# STM32L151 register map
File version: 1.5
CPU: CM3 r1p1, little endian, no MPU, no FPU, 4 interrupt priority bits
Registers are 32-bit, read-write, reset 0x0 unless marked. A register's access mark holds for its fields unless they carry their own. Offsets are from the block's base; [hi:lo] are bit positions; {n}, {i} and the like mark numbered series.

## USB — Universal serial bus full-speed device interface
Base 0x40005C00
Same registers: USB_SRAM 0x40006000
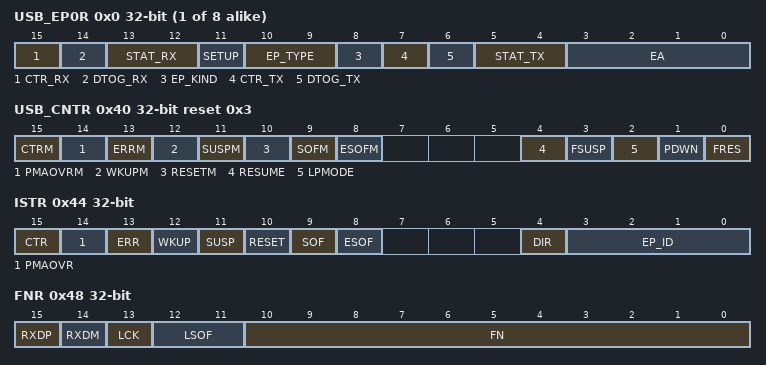
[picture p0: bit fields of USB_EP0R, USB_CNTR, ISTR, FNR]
{0x0+4i} USB_EP{i}R (i=0..7) — endpoint {i} register
  [15] CTR_RX — Correct transfer for reception
  [14] DTOG_RX — Data Toggle, for reception transfers
  [13:12] STAT_RX — Status bits, for reception transfers
  [11] SETUP — Setup transaction completed
  [10:9] EP_TYPE — Endpoint type
  [8] EP_KIND — Endpoint kind
  [7] CTR_TX — Correct Transfer for transmission
  [6] DTOG_TX — Data Toggle, for transmission transfers
  [5:4] STAT_TX — Status bits, for transmission transfers
  [3:0] EA — Endpoint address
0x40 USB_CNTR reset 0x3 — control register
  [15] CTRM — Correct transfer interrupt mask
  [14] PMAOVRM — Packet memory area over / underrun interrupt mask
  [13] ERRM — Error interrupt mask
  [12] WKUPM — Wakeup interrupt mask
  [11] SUSPM — Suspend mode interrupt mask
  [10] RESETM — USB reset interrupt mask
  [9] SOFM — Start of frame interrupt mask
  [8] ESOFM — Expected start of frame interrupt mask
  [4] RESUME — Resume request
  [3] FSUSP — Force suspend
  [2] LPMODE — Low-power mode
  [1] PDWN — Power down
  [0] FRES — Force USB Reset
0x44 ISTR — interrupt status register
  [15] CTR — Correct transfer
  [14] PMAOVR — Packet memory area over / underrun
  [13] ERR — Error
  [12] WKUP — Wakeup
  [11] SUSP — Suspend mode request
  [10] RESET — reset request
  [9] SOF — start of frame
  [8] ESOF — Expected start frame
  [4] DIR — Direction of transaction
  [3:0] EP_ID — Endpoint Identifier
0x48 FNR ro — frame number register
  [15] RXDP — Receive data + line status
  [14] RXDM — Receive data - line status
  [13] LCK — Locked
  [12:11] LSOF — Lost SOF
  [10:0] FN — Frame number
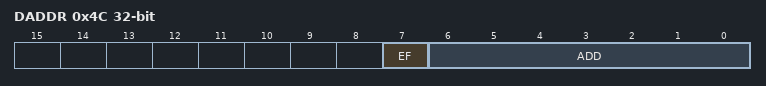
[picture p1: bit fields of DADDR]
0x4C DADDR — device address
  [7] EF — Enable function
  [6:0] ADD — Device address
0x50 BTABLE — Buffer table address
  [15:3] BTABLE — Buffer table

## WWDG — Window watchdog
Base 0x40002C00
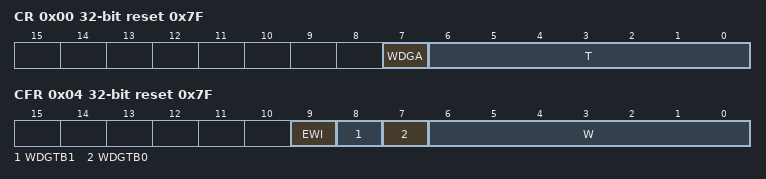
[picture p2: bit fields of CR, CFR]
0x00 CR access per field reset 0x7F — Control register
  [7] WDGA wo — Activation bit
  [6:0] T rw — 7-bit counter (MSB to LSB)
0x04 CFR access per field reset 0x7F — Configuration register
  [9] EWI wo — Early wakeup interrupt
  [8] WDGTB1 rw — Timer base
  [7] WDGTB0 rw
  [6:0] W rw — 7-bit window value
0x08 SR
  [0] EWIF

## NVIC — Nested Vectored Interrupt Controller
Base 0xE000E100
0x00 ISER0 — Interrupt Set-Enable Register
  [31:0] SETENA
0x04 ISER1 — Interrupt Set-Enable Register
  [31:0] SETENA
0x80 ICER0 — Interrupt Clear-Enable Register
  [31:0] CLRENA
0x84 ICER1 — Interrupt Clear-Enable Register
  [31:0] CLRENA
0x100 ISPR0 — Interrupt Set-Pending Register
  [31:0] SETPEND
0x104 ISPR1 — Interrupt Set-Pending Register
  [31:0] SETPEND
0x180 ICPR0 — Interrupt Clear-Pending Register
  [31:0] CLRPEND
0x184 ICPR1 — Interrupt Clear-Pending Register
  [31:0] CLRPEND
0x200 IABR0 ro — Interrupt Active Bit Register
  [31:0] ACTIVE
0x204 IABR1 ro — Interrupt Active Bit Register
  [31:0] ACTIVE
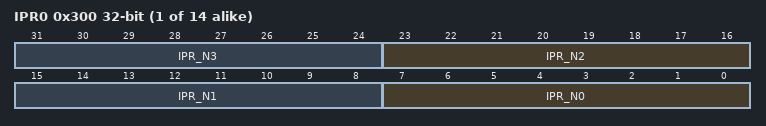
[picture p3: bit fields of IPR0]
{0x300+4i} IPR{i} (i=0..13) — Interrupt Priority Register
  [8n+7:8n] IPR_N{n} (n=0..3)

## DBGMCU — debug support
Base 0xE0042000
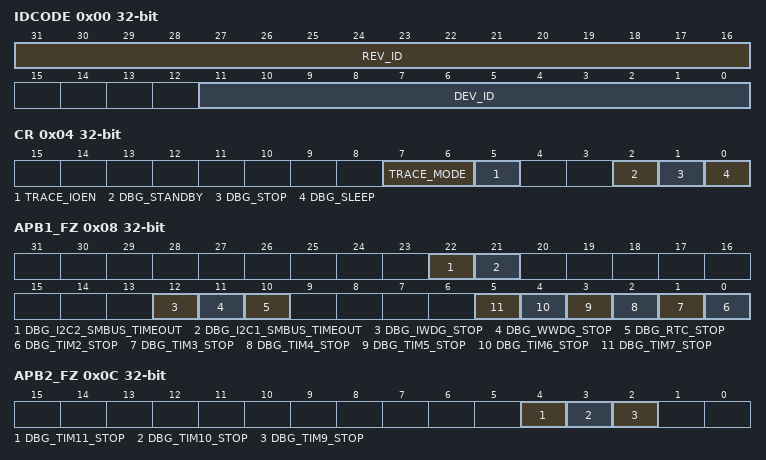
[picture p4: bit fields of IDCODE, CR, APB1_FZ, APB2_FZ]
0x00 IDCODE ro — DBGMCU_IDCODE
  [31:16] REV_ID — Revision identifie
  [11:0] DEV_ID — Device identifier
0x04 CR — Debug MCU configuration register
  [7:6] TRACE_MODE — Trace pin assignment control
  [5] TRACE_IOEN — Trace pin assignment control
  [2] DBG_STANDBY — Debug Standby mode
  [1] DBG_STOP — Debug Stop mode
  [0] DBG_SLEEP — Debug Sleep mode
0x08 APB1_FZ — Debug MCU APB1 freeze register1
  [22] DBG_I2C2_SMBUS_TIMEOUT — SMBUS timeout mode stopped when core is halted
  [21] DBG_I2C1_SMBUS_TIMEOUT — SMBUS timeout mode stopped when core is halted
  [12] DBG_IWDG_STOP — Debug independent watchdog stopped when core is halted
  [11] DBG_WWDG_STOP — Debug window watchdog stopped when core is halted
  [10] DBG_RTC_STOP — Debug RTC stopped when core is halted
  [n-2] DBG_TIM{n}_STOP (n=2..7) — TIM{n} counter stopped when core is halted
0x0C APB2_FZ — Debug MCU APB1 freeze register 2
  [4] DBG_TIM11_STOP — TIM counter stopped when core is halted
  [3] DBG_TIM10_STOP — TIM counter stopped when core is halted
  [2] DBG_TIM9_STOP — TIM counter stopped when core is halted

## MPU — Memory protection unit
Base 0xE000ED90
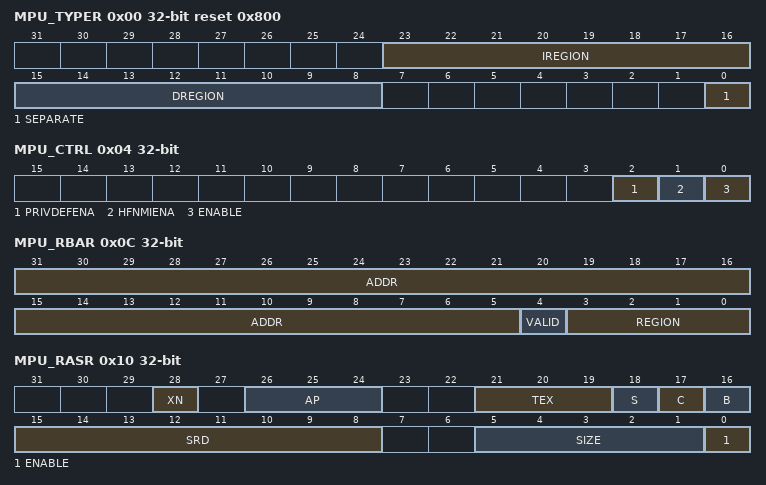
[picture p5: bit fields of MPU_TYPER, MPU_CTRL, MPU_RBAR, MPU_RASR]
0x00 MPU_TYPER ro reset 0x800 — MPU type register
  [23:16] IREGION — Number of MPU instruction regions
  [15:8] DREGION — Number of MPU data regions
  [0] SEPARATE — Separate flag
0x04 MPU_CTRL ro — MPU control register
  [2] PRIVDEFENA — Enable priviliged software access to default memory map
  [1] HFNMIENA — Enables the operation of MPU during hard fault
  [0] ENABLE — Enables the MPU
0x08 MPU_RNR — MPU region number register
  [7:0] REGION — MPU region
0x0C MPU_RBAR — MPU region base address register
  [31:5] ADDR — Region base address field
  [4] VALID — MPU region number valid
  [3:0] REGION — MPU region field
0x10 MPU_RASR — MPU region attribute and size register
  [28] XN — Instruction access disable bit
  [26:24] AP — Access permission
  [21:19] TEX — memory attribute
  [18] S — Shareable memory attribute
  [17] C — memory attribute
  [16] B — memory attribute
  [15:8] SRD — Subregion disable bits
  [5:1] SIZE — Size of the MPU protection region
  [0] ENABLE — Region enable bit.

## SCB_ACTRL — System control block ACTLR
Base 0xE000E008
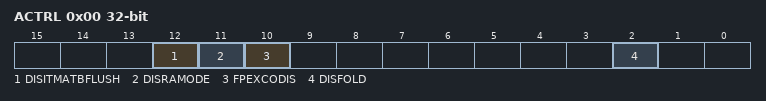
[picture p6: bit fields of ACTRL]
0x00 ACTRL — Auxiliary control register
  [12] DISITMATBFLUSH, [11] DISRAMODE, [10] FPEXCODIS, [2] DISFOLD

## NVIC_STIR — Nested vectored interrupt controller
Base 0xE000EF00
0x00 STIR — Software trigger interrupt register
  [8:0] INTID — Software generated interrupt ID

## STK — SysTick timer
Base 0xE000E010
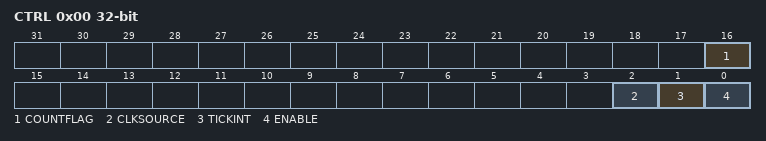
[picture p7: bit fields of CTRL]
0x00 CTRL — SysTick control and status register
  [16] COUNTFLAG
  [2] CLKSOURCE — Clock source selection
  [1] TICKINT — SysTick exception request enable
  [0] ENABLE — Counter enable
0x04 LOAD_ — SysTick reload value register
  [23:0] RELOAD — RELOAD value
0x08 VAL — SysTick current value register
  [23:0] CURRENT — Current counter value
0x0C CALIB — SysTick calibration value register
  [23:0] TENMS — Calibration value
